AUTOSAR XML (schema 4-2-1)
standard types defined: boolean, float32, uint8, boolean_CompuMethod, boolean_DataConstr, float32_DataConstr, uint8_DataConstr
package /ComponentTypes
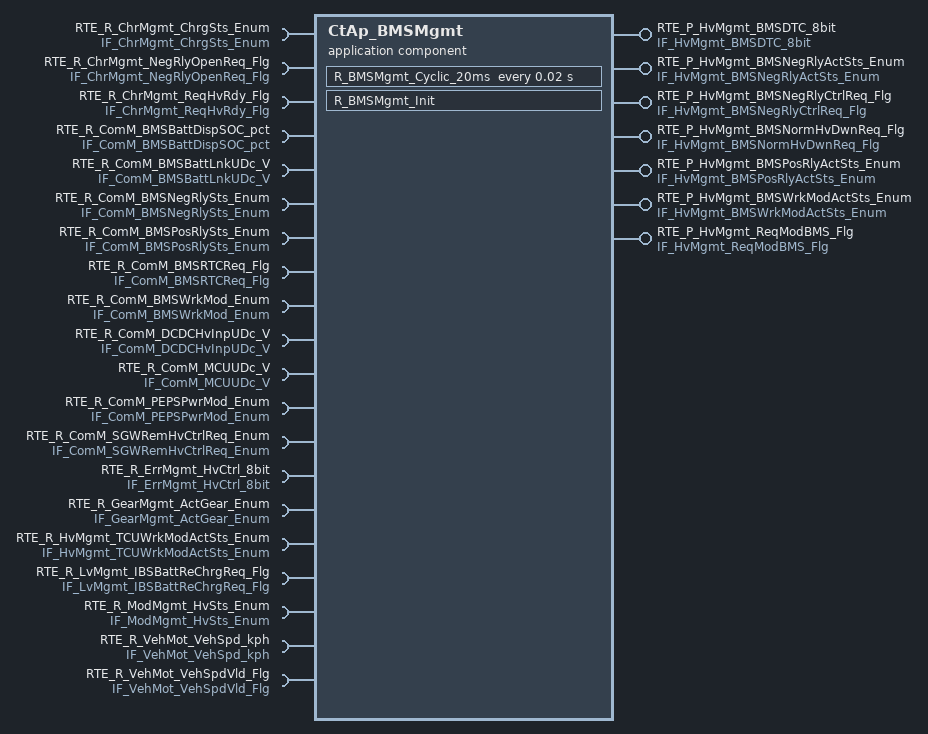
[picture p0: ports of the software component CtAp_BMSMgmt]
  application sw component type CtAp_BMSMgmt
    7 x provide port:
      RTE_P_HvMgmt_BMSDTC_8bit: nonqueued-sender-com-spec{data-element=tec_HvMgmt_BMSDTC_8bit, init-value=0}, provided-interface=IF_HvMgmt_BMSDTC_8bit
      RTE_P_HvMgmt_BMSNegRlyActSts_Enum: nonqueued-sender-com-spec{data-element=tec_HvMgmt_BMSNegRlyActSts_Enum, init-value=0}, provided-interface=IF_HvMgmt_BMSNegRlyActSts_Enum
      RTE_P_HvMgmt_BMSNegRlyCtrlReq_Flg: nonqueued-sender-com-spec{data-element=tec_HvMgmt_BMSNegRlyCtrlReq_Flg, init-value=0}, provided-interface=IF_HvMgmt_BMSNegRlyCtrlReq_Flg
      RTE_P_HvMgmt_BMSNormHvDwnReq_Flg: nonqueued-sender-com-spec{data-element=tec_HvMgmt_BMSNormHvDwnReq_Flg, init-value=0}, provided-interface=IF_HvMgmt_BMSNormHvDwnReq_Flg
      RTE_P_HvMgmt_BMSPosRlyActSts_Enum: nonqueued-sender-com-spec{data-element=tec_HvMgmt_BMSPosRlyActSts_Enum, init-value=0}, provided-interface=IF_HvMgmt_BMSPosRlyActSts_Enum
      RTE_P_HvMgmt_BMSWrkModActSts_Enum: nonqueued-sender-com-spec{data-element=tec_HvMgmt_BMSWrkModActSts_Enum, init-value=0}, provided-interface=IF_HvMgmt_BMSWrkModActSts_Enum
      RTE_P_HvMgmt_ReqModBMS_Flg: nonqueued-sender-com-spec{data-element=tec_HvMgmt_ReqModBMS_Flg, init-value=0}, provided-interface=IF_HvMgmt_ReqModBMS_Flg
    20 x require port:
      RTE_R_ChrMgmt_ChrgSts_Enum: nonqueued-receiver-com-spec{data-element=tec_ChrMgmt_ChrgSts_Enum, filter=data-filter-type=ALWAYS, init-value=0}, required-interface=IF_ChrMgmt_ChrgSts_Enum
      RTE_R_ChrMgmt_NegRlyOpenReq_Flg: nonqueued-receiver-com-spec{data-element=tec_ChrMgmt_NegRlyOpenReq_Flg, filter=data-filter-type=ALWAYS, init-value=0}, required-interface=IF_ChrMgmt_NegRlyOpenReq_Flg
      RTE_R_ChrMgmt_ReqHvRdy_Flg: nonqueued-receiver-com-spec{data-element=tec_ChrMgmt_ReqHvRdy_Flg, filter=data-filter-type=ALWAYS, init-value=0}, required-interface=IF_ChrMgmt_ReqHvRdy_Flg
      RTE_R_ComM_BMSBattDispSOC_pct: nonqueued-receiver-com-spec{data-element=tec_ComM_BMSBattDispSOC_pct, filter=data-filter-type=ALWAYS, init-value=0}, required-interface=IF_ComM_BMSBattDispSOC_pct
      RTE_R_ComM_BMSBattLnkUDc_V: nonqueued-receiver-com-spec{data-element=tec_ComM_BMSBattLnkUDc_V, filter=data-filter-type=ALWAYS, init-value=0}, required-interface=IF_ComM_BMSBattLnkUDc_V
      RTE_R_ComM_BMSNegRlySts_Enum: nonqueued-receiver-com-spec{data-element=tec_ComM_BMSNegRlySts_Enum, filter=data-filter-type=ALWAYS, init-value=0}, required-interface=IF_ComM_BMSNegRlySts_Enum
      RTE_R_ComM_BMSPosRlySts_Enum: nonqueued-receiver-com-spec{data-element=tec_ComM_BMSPosRlySts_Enum, filter=data-filter-type=ALWAYS, init-value=0}, required-interface=IF_ComM_BMSPosRlySts_Enum
      RTE_R_ComM_BMSRTCReq_Flg: nonqueued-receiver-com-spec{data-element=tec_ComM_BMSRTCReq_Flg, filter=data-filter-type=ALWAYS, init-value=0}, required-interface=IF_ComM_BMSRTCReq_Flg
      RTE_R_ComM_BMSWrkMod_Enum: nonqueued-receiver-com-spec{data-element=tec_ComM_BMSWrkMod_Enum, filter=data-filter-type=ALWAYS, init-value=0}, required-interface=IF_ComM_BMSWrkMod_Enum
      RTE_R_ComM_DCDCHvInpUDc_V: nonqueued-receiver-com-spec{data-element=tec_ComM_DCDCHvInpUDc_V, filter=data-filter-type=ALWAYS, init-value=0}, required-interface=IF_ComM_DCDCHvInpUDc_V
      RTE_R_ComM_MCUUDc_V: nonqueued-receiver-com-spec{data-element=tec_ComM_MCUUDc_V, filter=data-filter-type=ALWAYS, init-value=0}, required-interface=IF_ComM_MCUUDc_V
      RTE_R_ComM_PEPSPwrMod_Enum: nonqueued-receiver-com-spec{data-element=tec_ComM_PEPSPwrMod_Enum, filter=data-filter-type=ALWAYS, init-value=0}, required-interface=IF_ComM_PEPSPwrMod_Enum
      RTE_R_ComM_SGWRemHvCtrlReq_Enum: nonqueued-receiver-com-spec{data-element=tec_ComM_SGWRemHvCtrlReq_Enum, filter=data-filter-type=ALWAYS, init-value=0}, required-interface=IF_ComM_SGWRemHvCtrlReq_Enum
      RTE_R_ErrMgmt_HvCtrl_8bit: nonqueued-receiver-com-spec{data-element=tec_ErrMgmt_HvCtrl_8bit, filter=data-filter-type=ALWAYS, init-value=0}, required-interface=IF_ErrMgmt_HvCtrl_8bit
      RTE_R_GearMgmt_ActGear_Enum: nonqueued-receiver-com-spec{data-element=tec_GearMgmt_ActGear_Enum, filter=data-filter-type=ALWAYS, init-value=0}, required-interface=IF_GearMgmt_ActGear_Enum
      RTE_R_HvMgmt_TCUWrkModActSts_Enum: nonqueued-receiver-com-spec{data-element=tec_HvMgmt_TCUWrkModActSts_Enum, filter=data-filter-type=ALWAYS, init-value=0}, required-interface=IF_HvMgmt_TCUWrkModActSts_Enum
      RTE_R_LvMgmt_IBSBattReChrgReq_Flg: nonqueued-receiver-com-spec{data-element=tec_LvMgmt_IBSBattReChrgReq_Flg, filter=data-filter-type=ALWAYS, init-value=0}, required-interface=IF_LvMgmt_IBSBattReChrgReq_Flg
      RTE_R_ModMgmt_HvSts_Enum: nonqueued-receiver-com-spec{data-element=tec_ModMgmt_HvSts_Enum, filter=data-filter-type=ALWAYS, init-value=0}, required-interface=IF_ModMgmt_HvSts_Enum
      RTE_R_VehMot_VehSpd_kph: nonqueued-receiver-com-spec{data-element=tec_VehMot_VehSpd_kph, filter=data-filter-type=ALWAYS, init-value=0}, required-interface=IF_VehMot_VehSpd_kph
      RTE_R_VehMot_VehSpdVld_Flg: nonqueued-receiver-com-spec{data-element=tec_VehMot_VehSpdVld_Flg, filter=data-filter-type=ALWAYS, init-value=0}, required-interface=IF_VehMot_VehSpdVld_Flg
    behavior CtAp_BMSMgmt_InternalBehavior
      timing event TMT_R_BMSMgmt_Cyclic_20ms: start-on-event=R_BMSMgmt_Cyclic_20ms, period=0.02
      init event CtAp_BMSMgmt_InitEvent: start-on-event=R_BMSMgmt_Init
      runnable R_BMSMgmt_Cyclic_20ms
        data-receive-point-by-arguments:
          20 x access:
            REC_RTE_R_ChrMgmt_ChrgSts_Enum_tec_ChrMgmt_ChrgSts_Enum: accessed-variable=RTE_R_ChrMgmt_ChrgSts_Enum.tec_ChrMgmt_ChrgSts_Enum
            REC_RTE_R_ChrMgmt_NegRlyOpenReq_Flg_tec_ChrMgmt_NegRlyOpenReq_Flg: accessed-variable=RTE_R_ChrMgmt_NegRlyOpenReq_Flg.tec_ChrMgmt_NegRlyOpenReq_Flg
            REC_RTE_R_ChrMgmt_ReqHvRdy_Flg_tec_ChrMgmt_ReqHvRdy_Flg: accessed-variable=RTE_R_ChrMgmt_ReqHvRdy_Flg.tec_ChrMgmt_ReqHvRdy_Flg
            REC_RTE_R_ComM_BMSBattDispSOC_pct_tec_ComM_BMSBattDispSOC_pct: accessed-variable=RTE_R_ComM_BMSBattDispSOC_pct.tec_ComM_BMSBattDispSOC_pct
            REC_RTE_R_ComM_BMSBattLnkUDc_V_tec_ComM_BMSBattLnkUDc_V: accessed-variable=RTE_R_ComM_BMSBattLnkUDc_V.tec_ComM_BMSBattLnkUDc_V
            REC_RTE_R_ComM_BMSNegRlySts_Enum_tec_ComM_BMSNegRlySts_Enum: accessed-variable=RTE_R_ComM_BMSNegRlySts_Enum.tec_ComM_BMSNegRlySts_Enum
            REC_RTE_R_ComM_BMSPosRlySts_Enum_tec_ComM_BMSPosRlySts_Enum: accessed-variable=RTE_R_ComM_BMSPosRlySts_Enum.tec_ComM_BMSPosRlySts_Enum
            REC_RTE_R_ComM_BMSRTCReq_Flg_tec_ComM_BMSRTCReq_Flg: accessed-variable=RTE_R_ComM_BMSRTCReq_Flg.tec_ComM_BMSRTCReq_Flg
            REC_RTE_R_ComM_BMSWrkMod_Enum_tec_ComM_BMSWrkMod_Enum: accessed-variable=RTE_R_ComM_BMSWrkMod_Enum.tec_ComM_BMSWrkMod_Enum
            REC_RTE_R_ComM_DCDCHvInpUDc_V_tec_ComM_DCDCHvInpUDc_V: accessed-variable=RTE_R_ComM_DCDCHvInpUDc_V.tec_ComM_DCDCHvInpUDc_V
            REC_RTE_R_ComM_MCUUDc_V_tec_ComM_MCUUDc_V: accessed-variable=RTE_R_ComM_MCUUDc_V.tec_ComM_MCUUDc_V
            REC_RTE_R_ComM_PEPSPwrMod_Enum_tec_ComM_PEPSPwrMod_Enum: accessed-variable=RTE_R_ComM_PEPSPwrMod_Enum.tec_ComM_PEPSPwrMod_Enum
            REC_RTE_R_ComM_SGWRemHvCtrlReq_Enum_tec_ComM_SGWRemHvCtrlReq_Enum: accessed-variable=RTE_R_ComM_SGWRemHvCtrlReq_Enum.tec_ComM_SGWRemHvCtrlReq_Enum
            REC_RTE_R_ErrMgmt_HvCtrl_8bit_tec_ErrMgmt_HvCtrl_8bit: accessed-variable=RTE_R_ErrMgmt_HvCtrl_8bit.tec_ErrMgmt_HvCtrl_8bit
            REC_RTE_R_GearMgmt_ActGear_Enum_tec_GearMgmt_ActGear_Enum: accessed-variable=RTE_R_GearMgmt_ActGear_Enum.tec_GearMgmt_ActGear_Enum
            REC_RTE_R_HvMgmt_TCUWrkModActSts_Enum_tec_HvMgmt_TCUWrkModActSts_Enum: accessed-variable=RTE_R_HvMgmt_TCUWrkModActSts_Enum.tec_HvMgmt_TCUWrkModActSts_Enum
            REC_RTE_R_LvMgmt_IBSBattReChrgReq_Flg_tec_LvMgmt_IBSBattReChrgReq_Flg: accessed-variable=RTE_R_LvMgmt_IBSBattReChrgReq_Flg.tec_LvMgmt_IBSBattReChrgReq_Flg
            REC_RTE_R_ModMgmt_HvSts_Enum_tec_ModMgmt_HvSts_Enum: accessed-variable=RTE_R_ModMgmt_HvSts_Enum.tec_ModMgmt_HvSts_Enum
            REC_RTE_R_VehMot_VehSpd_kph_tec_VehMot_VehSpd_kph: accessed-variable=RTE_R_VehMot_VehSpd_kph.tec_VehMot_VehSpd_kph
            REC_RTE_R_VehMot_VehSpdVld_Flg_tec_VehMot_VehSpdVld_Flg: accessed-variable=RTE_R_VehMot_VehSpdVld_Flg.tec_VehMot_VehSpdVld_Flg
        data-send-points:
          7 x access:
            SEND_RTE_P_HvMgmt_BMSDTC_8bit_tec_HvMgmt_BMSDTC_8bit: accessed-variable=RTE_P_HvMgmt_BMSDTC_8bit.tec_HvMgmt_BMSDTC_8bit
            SEND_RTE_P_HvMgmt_BMSNegRlyActSts_Enum_tec_HvMgmt_BMSNegRlyActSts_Enum: accessed-variable=RTE_P_HvMgmt_BMSNegRlyActSts_Enum.tec_HvMgmt_BMSNegRlyActSts_Enum
            SEND_RTE_P_HvMgmt_BMSNegRlyCtrlReq_Flg_tec_HvMgmt_BMSNegRlyCtrlReq_Flg: accessed-variable=RTE_P_HvMgmt_BMSNegRlyCtrlReq_Flg.tec_HvMgmt_BMSNegRlyCtrlReq_Flg
            SEND_RTE_P_HvMgmt_BMSNormHvDwnReq_Flg_tec_HvMgmt_BMSNormHvDwnReq_Flg: accessed-variable=RTE_P_HvMgmt_BMSNormHvDwnReq_Flg.tec_HvMgmt_BMSNormHvDwnReq_Flg
            SEND_RTE_P_HvMgmt_BMSPosRlyActSts_Enum_tec_HvMgmt_BMSPosRlyActSts_Enum: accessed-variable=RTE_P_HvMgmt_BMSPosRlyActSts_Enum.tec_HvMgmt_BMSPosRlyActSts_Enum
            SEND_RTE_P_HvMgmt_BMSWrkModActSts_Enum_tec_HvMgmt_BMSWrkModActSts_Enum: accessed-variable=RTE_P_HvMgmt_BMSWrkModActSts_Enum.tec_HvMgmt_BMSWrkModActSts_Enum
            SEND_RTE_P_HvMgmt_ReqModBMS_Flg_tec_HvMgmt_ReqModBMS_Flg: accessed-variable=RTE_P_HvMgmt_ReqModBMS_Flg.tec_HvMgmt_ReqModBMS_Flg
      runnable R_BMSMgmt_Init
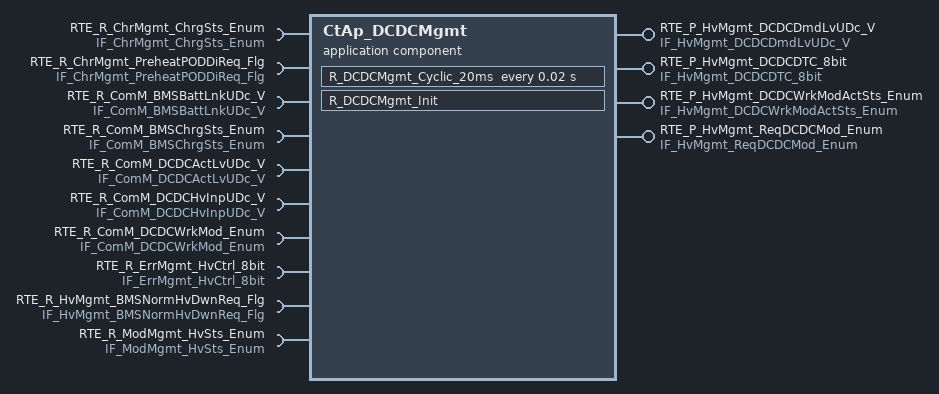
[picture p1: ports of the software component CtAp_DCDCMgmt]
  application sw component type CtAp_DCDCMgmt
    4 x provide port:
      RTE_P_HvMgmt_DCDCDmdLvUDc_V: nonqueued-sender-com-spec{data-element=tec_HvMgmt_DCDCDmdLvUDc_V, init-value=0}, provided-interface=IF_HvMgmt_DCDCDmdLvUDc_V
      RTE_P_HvMgmt_DCDCDTC_8bit: nonqueued-sender-com-spec{data-element=tec_HvMgmt_DCDCDTC_8bit, init-value=0}, provided-interface=IF_HvMgmt_DCDCDTC_8bit
      RTE_P_HvMgmt_DCDCWrkModActSts_Enum: nonqueued-sender-com-spec{data-element=tec_HvMgmt_DCDCWrkModActSts_Enum, init-value=0}, provided-interface=IF_HvMgmt_DCDCWrkModActSts_Enum
      RTE_P_HvMgmt_ReqDCDCMod_Enum: nonqueued-sender-com-spec{data-element=tec_HvMgmt_ReqDCDCMod_Enum, init-value=0}, provided-interface=IF_HvMgmt_ReqDCDCMod_Enum
    10 x require port:
      RTE_R_ChrMgmt_ChrgSts_Enum: nonqueued-receiver-com-spec{data-element=tec_ChrMgmt_ChrgSts_Enum, filter=data-filter-type=ALWAYS, init-value=0}, required-interface=IF_ChrMgmt_ChrgSts_Enum
      RTE_R_ChrMgmt_PreheatPODDiReq_Flg: nonqueued-receiver-com-spec{data-element=tec_ChrMgmt_PreheatPODDiReq_Flg, filter=data-filter-type=ALWAYS, init-value=0}, required-interface=IF_ChrMgmt_PreheatPODDiReq_Flg
      RTE_R_ComM_BMSBattLnkUDc_V: nonqueued-receiver-com-spec{data-element=tec_ComM_BMSBattLnkUDc_V, filter=data-filter-type=ALWAYS, init-value=0}, required-interface=IF_ComM_BMSBattLnkUDc_V
      RTE_R_ComM_BMSChrgSts_Enum: nonqueued-receiver-com-spec{data-element=tec_ComM_BMSChrgSts_Enum, filter=data-filter-type=ALWAYS, init-value=0}, required-interface=IF_ComM_BMSChrgSts_Enum
      RTE_R_ComM_DCDCActLvUDc_V: nonqueued-receiver-com-spec{data-element=tec_ComM_DCDCActLvUDc_V, filter=data-filter-type=ALWAYS, init-value=0}, required-interface=IF_ComM_DCDCActLvUDc_V
      RTE_R_ComM_DCDCHvInpUDc_V: nonqueued-receiver-com-spec{data-element=tec_ComM_DCDCHvInpUDc_V, filter=data-filter-type=ALWAYS, init-value=0}, required-interface=IF_ComM_DCDCHvInpUDc_V
      RTE_R_ComM_DCDCWrkMod_Enum: nonqueued-receiver-com-spec{data-element=tec_ComM_DCDCWrkMod_Enum, filter=data-filter-type=ALWAYS, init-value=0}, required-interface=IF_ComM_DCDCWrkMod_Enum
      RTE_R_ErrMgmt_HvCtrl_8bit: nonqueued-receiver-com-spec{data-element=tec_ErrMgmt_HvCtrl_8bit, filter=data-filter-type=ALWAYS, init-value=0}, required-interface=IF_ErrMgmt_HvCtrl_8bit
      RTE_R_HvMgmt_BMSNormHvDwnReq_Flg: nonqueued-receiver-com-spec{data-element=tec_HvMgmt_BMSNormHvDwnReq_Flg, filter=data-filter-type=ALWAYS, init-value=0}, required-interface=IF_HvMgmt_BMSNormHvDwnReq_Flg
      RTE_R_ModMgmt_HvSts_Enum: nonqueued-receiver-com-spec{data-element=tec_ModMgmt_HvSts_Enum, filter=data-filter-type=ALWAYS, init-value=0}, required-interface=IF_ModMgmt_HvSts_Enum
    behavior CtAp_DCDCMgmt_InternalBehavior
      timing event TMT_R_DCDCMgmt_Cyclic_20ms: start-on-event=R_DCDCMgmt_Cyclic_20ms, period=0.02
      init event CtAp_DCDCMgmt_InitEvent: start-on-event=R_DCDCMgmt_Init
      runnable R_DCDCMgmt_Cyclic_20ms
        data-receive-point-by-arguments:
          10 x access:
            REC_RTE_R_ChrMgmt_ChrgSts_Enum_tec_ChrMgmt_ChrgSts_Enum: accessed-variable=RTE_R_ChrMgmt_ChrgSts_Enum.tec_ChrMgmt_ChrgSts_Enum
            REC_RTE_R_ChrMgmt_PreheatPODDiReq_Flg_tec_ChrMgmt_PreheatPODDiReq_Flg: accessed-variable=RTE_R_ChrMgmt_PreheatPODDiReq_Flg.tec_ChrMgmt_PreheatPODDiReq_Flg
            REC_RTE_R_ComM_BMSBattLnkUDc_V_tec_ComM_BMSBattLnkUDc_V: accessed-variable=RTE_R_ComM_BMSBattLnkUDc_V.tec_ComM_BMSBattLnkUDc_V
            REC_RTE_R_ComM_BMSChrgSts_Enum_tec_ComM_BMSChrgSts_Enum: accessed-variable=RTE_R_ComM_BMSChrgSts_Enum.tec_ComM_BMSChrgSts_Enum
            REC_RTE_R_ComM_DCDCActLvUDc_V_tec_ComM_DCDCActLvUDc_V: accessed-variable=RTE_R_ComM_DCDCActLvUDc_V.tec_ComM_DCDCActLvUDc_V
            REC_RTE_R_ComM_DCDCHvInpUDc_V_tec_ComM_DCDCHvInpUDc_V: accessed-variable=RTE_R_ComM_DCDCHvInpUDc_V.tec_ComM_DCDCHvInpUDc_V
            REC_RTE_R_ComM_DCDCWrkMod_Enum_tec_ComM_DCDCWrkMod_Enum: accessed-variable=RTE_R_ComM_DCDCWrkMod_Enum.tec_ComM_DCDCWrkMod_Enum
            REC_RTE_R_ErrMgmt_HvCtrl_8bit_tec_ErrMgmt_HvCtrl_8bit: accessed-variable=RTE_R_ErrMgmt_HvCtrl_8bit.tec_ErrMgmt_HvCtrl_8bit
            REC_RTE_R_HvMgmt_BMSNormHvDwnReq_Flg_tec_HvMgmt_BMSNormHvDwnReq_Flg: accessed-variable=RTE_R_HvMgmt_BMSNormHvDwnReq_Flg.tec_HvMgmt_BMSNormHvDwnReq_Flg
            REC_RTE_R_ModMgmt_HvSts_Enum_tec_ModMgmt_HvSts_Enum: accessed-variable=RTE_R_ModMgmt_HvSts_Enum.tec_ModMgmt_HvSts_Enum
        data-send-points:
          4 x access:
            SEND_RTE_P_HvMgmt_DCDCDmdLvUDc_V_tec_HvMgmt_DCDCDmdLvUDc_V: accessed-variable=RTE_P_HvMgmt_DCDCDmdLvUDc_V.tec_HvMgmt_DCDCDmdLvUDc_V
            SEND_RTE_P_HvMgmt_DCDCDTC_8bit_tec_HvMgmt_DCDCDTC_8bit: accessed-variable=RTE_P_HvMgmt_DCDCDTC_8bit.tec_HvMgmt_DCDCDTC_8bit
            SEND_RTE_P_HvMgmt_DCDCWrkModActSts_Enum_tec_HvMgmt_DCDCWrkModActSts_Enum: accessed-variable=RTE_P_HvMgmt_DCDCWrkModActSts_Enum.tec_HvMgmt_DCDCWrkModActSts_Enum
            SEND_RTE_P_HvMgmt_ReqDCDCMod_Enum_tec_HvMgmt_ReqDCDCMod_Enum: accessed-variable=RTE_P_HvMgmt_ReqDCDCMod_Enum.tec_HvMgmt_ReqDCDCMod_Enum
      runnable R_DCDCMgmt_Init
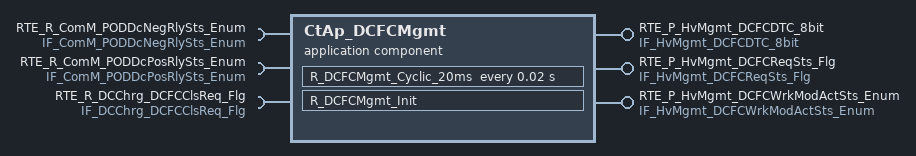
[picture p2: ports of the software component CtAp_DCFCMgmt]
  application sw component type CtAp_DCFCMgmt
    provide port RTE_P_HvMgmt_DCFCDTC_8bit: nonqueued-sender-com-spec{data-element=tec_HvMgmt_DCFCDTC_8bit, init-value=0}, provided-interface=IF_HvMgmt_DCFCDTC_8bit
    provide port RTE_P_HvMgmt_DCFCReqSts_Flg: nonqueued-sender-com-spec{data-element=tec_HvMgmt_DCFCReqSts_Flg, init-value=0}, provided-interface=IF_HvMgmt_DCFCReqSts_Flg
    provide port RTE_P_HvMgmt_DCFCWrkModActSts_Enum: nonqueued-sender-com-spec{data-element=tec_HvMgmt_DCFCWrkModActSts_Enum, init-value=0}, provided-interface=IF_HvMgmt_DCFCWrkModActSts_Enum
    require port RTE_R_ComM_PODDcNegRlySts_Enum: nonqueued-receiver-com-spec{data-element=tec_ComM_PODDcNegRlySts_Enum, filter=data-filter-type=ALWAYS, init-value=0}, required-interface=IF_ComM_PODDcNegRlySts_Enum
    require port RTE_R_ComM_PODDcPosRlySts_Enum: nonqueued-receiver-com-spec{data-element=tec_ComM_PODDcPosRlySts_Enum, filter=data-filter-type=ALWAYS, init-value=0}, required-interface=IF_ComM_PODDcPosRlySts_Enum
    require port RTE_R_DCChrg_DCFCClsReq_Flg: nonqueued-receiver-com-spec{data-element=tec_DCChrg_DCFCClsReq_Flg, filter=data-filter-type=ALWAYS, init-value=0}, required-interface=IF_DCChrg_DCFCClsReq_Flg
    behavior CtAp_DCFCMgmt_InternalBehavior
      timing event TMT_R_DCFCMgmt_Cyclic_20ms: start-on-event=R_DCFCMgmt_Cyclic_20ms, period=0.02
      init event CtAp_DCFCMgmt_InitEvent: start-on-event=R_DCFCMgmt_Init
      runnable R_DCFCMgmt_Cyclic_20ms
        data-receive-point-by-arguments:
          access REC_RTE_R_ComM_PODDcNegRlySts_Enum_tec_ComM_PODDcNegRlySts_Enum: accessed-variable=RTE_R_ComM_PODDcNegRlySts_Enum.tec_ComM_PODDcNegRlySts_Enum
          access REC_RTE_R_ComM_PODDcPosRlySts_Enum_tec_ComM_PODDcPosRlySts_Enum: accessed-variable=RTE_R_ComM_PODDcPosRlySts_Enum.tec_ComM_PODDcPosRlySts_Enum
          access REC_RTE_R_DCChrg_DCFCClsReq_Flg_tec_DCChrg_DCFCClsReq_Flg: accessed-variable=RTE_R_DCChrg_DCFCClsReq_Flg.tec_DCChrg_DCFCClsReq_Flg
        data-send-points:
          access SEND_RTE_P_HvMgmt_DCFCDTC_8bit_tec_HvMgmt_DCFCDTC_8bit: accessed-variable=RTE_P_HvMgmt_DCFCDTC_8bit.tec_HvMgmt_DCFCDTC_8bit
          access SEND_RTE_P_HvMgmt_DCFCReqSts_Flg_tec_HvMgmt_DCFCReqSts_Flg: accessed-variable=RTE_P_HvMgmt_DCFCReqSts_Flg.tec_HvMgmt_DCFCReqSts_Flg
          access SEND_RTE_P_HvMgmt_DCFCWrkModActSts_Enum_tec_HvMgmt_DCFCWrkModActSts_Enum: accessed-variable=RTE_P_HvMgmt_DCFCWrkModActSts_Enum.tec_HvMgmt_DCFCWrkModActSts_Enum
      runnable R_DCFCMgmt_Init
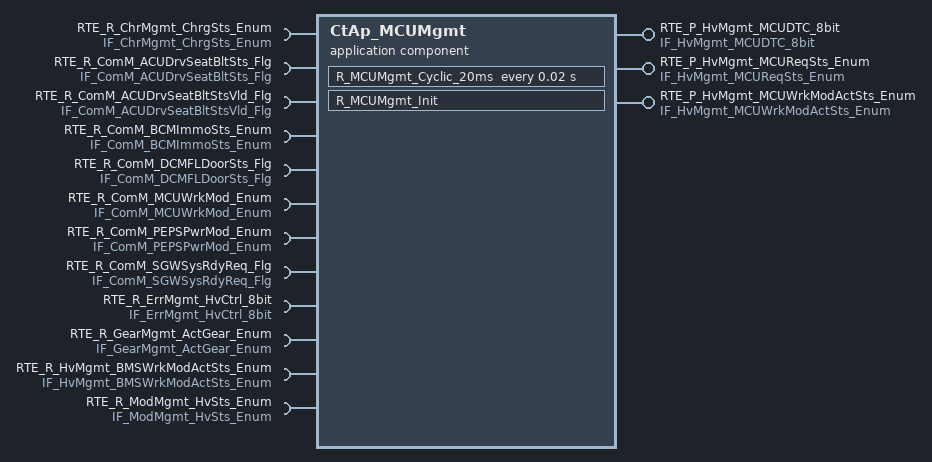
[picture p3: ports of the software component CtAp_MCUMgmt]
  application sw component type CtAp_MCUMgmt
    provide port RTE_P_HvMgmt_MCUDTC_8bit: nonqueued-sender-com-spec{data-element=tec_HvMgmt_MCUDTC_8bit, init-value=0}, provided-interface=IF_HvMgmt_MCUDTC_8bit
    provide port RTE_P_HvMgmt_MCUReqSts_Enum: nonqueued-sender-com-spec{data-element=tec_HvMgmt_MCUReqSts_Enum, init-value=0}, provided-interface=IF_HvMgmt_MCUReqSts_Enum
    provide port RTE_P_HvMgmt_MCUWrkModActSts_Enum: nonqueued-sender-com-spec{data-element=tec_HvMgmt_MCUWrkModActSts_Enum, init-value=0}, provided-interface=IF_HvMgmt_MCUWrkModActSts_Enum
    12 x require port:
      RTE_R_ChrMgmt_ChrgSts_Enum: nonqueued-receiver-com-spec{data-element=tec_ChrMgmt_ChrgSts_Enum, filter=data-filter-type=ALWAYS, init-value=0}, required-interface=IF_ChrMgmt_ChrgSts_Enum
      RTE_R_ComM_ACUDrvSeatBltSts_Flg: nonqueued-receiver-com-spec{data-element=tec_ComM_ACUDrvSeatBltSts_Flg, filter=data-filter-type=ALWAYS, init-value=0}, required-interface=IF_ComM_ACUDrvSeatBltSts_Flg
      RTE_R_ComM_ACUDrvSeatBltStsVld_Flg: nonqueued-receiver-com-spec{data-element=tec_ComM_ACUDrvSeatBltStsVld_Flg, filter=data-filter-type=ALWAYS, init-value=0}, required-interface=IF_ComM_ACUDrvSeatBltStsVld_Flg
      RTE_R_ComM_BCMImmoSts_Enum: nonqueued-receiver-com-spec{data-element=tec_ComM_BCMImmoSts_Enum, filter=data-filter-type=ALWAYS, init-value=0}, required-interface=IF_ComM_BCMImmoSts_Enum
      RTE_R_ComM_DCMFLDoorSts_Flg: nonqueued-receiver-com-spec{data-element=tec_ComM_DCMFLDoorSts_Flg, filter=data-filter-type=ALWAYS, init-value=0}, required-interface=IF_ComM_DCMFLDoorSts_Flg
      RTE_R_ComM_MCUWrkMod_Enum: nonqueued-receiver-com-spec{data-element=tec_ComM_MCUWrkMod_Enum, filter=data-filter-type=ALWAYS, init-value=0}, required-interface=IF_ComM_MCUWrkMod_Enum
      RTE_R_ComM_PEPSPwrMod_Enum: nonqueued-receiver-com-spec{data-element=tec_ComM_PEPSPwrMod_Enum, filter=data-filter-type=ALWAYS, init-value=0}, required-interface=IF_ComM_PEPSPwrMod_Enum
      RTE_R_ComM_SGWSysRdyReq_Flg: nonqueued-receiver-com-spec{data-element=tec_ComM_SGWSysRdyReq_Flg, filter=data-filter-type=ALWAYS, init-value=0}, required-interface=IF_ComM_SGWSysRdyReq_Flg
      RTE_R_ErrMgmt_HvCtrl_8bit: nonqueued-receiver-com-spec{data-element=tec_ErrMgmt_HvCtrl_8bit, filter=data-filter-type=ALWAYS, init-value=0}, required-interface=IF_ErrMgmt_HvCtrl_8bit
      RTE_R_GearMgmt_ActGear_Enum: nonqueued-receiver-com-spec{data-element=tec_GearMgmt_ActGear_Enum, filter=data-filter-type=ALWAYS, init-value=0}, required-interface=IF_GearMgmt_ActGear_Enum
      RTE_R_HvMgmt_BMSWrkModActSts_Enum: nonqueued-receiver-com-spec{data-element=tec_HvMgmt_BMSWrkModActSts_Enum, filter=data-filter-type=ALWAYS, init-value=0}, required-interface=IF_HvMgmt_BMSWrkModActSts_Enum
      RTE_R_ModMgmt_HvSts_Enum: nonqueued-receiver-com-spec{data-element=tec_ModMgmt_HvSts_Enum, filter=data-filter-type=ALWAYS, init-value=0}, required-interface=IF_ModMgmt_HvSts_Enum
    behavior CtAp_MCUMgmt_InternalBehavior
      timing event TMT_R_MCUMgmt_Cyclic_20ms: start-on-event=R_MCUMgmt_Cyclic_20ms, period=0.02
      init event CtAp_MCUMgmt_InitEvent: start-on-event=R_MCUMgmt_Init
      runnable R_MCUMgmt_Cyclic_20ms
        data-receive-point-by-arguments:
          12 x access:
            REC_RTE_R_ChrMgmt_ChrgSts_Enum_tec_ChrMgmt_ChrgSts_Enum: accessed-variable=RTE_R_ChrMgmt_ChrgSts_Enum.tec_ChrMgmt_ChrgSts_Enum
            REC_RTE_R_ComM_ACUDrvSeatBltSts_Flg_tec_ComM_ACUDrvSeatBltSts_Flg: accessed-variable=RTE_R_ComM_ACUDrvSeatBltSts_Flg.tec_ComM_ACUDrvSeatBltSts_Flg
            REC_RTE_R_ComM_ACUDrvSeatBltStsVld_Flg_tec_ComM_ACUDrvSeatBltStsVld_Flg: accessed-variable=RTE_R_ComM_ACUDrvSeatBltStsVld_Flg.tec_ComM_ACUDrvSeatBltStsVld_Flg
            REC_RTE_R_ComM_BCMImmoSts_Enum_tec_ComM_BCMImmoSts_Enum: accessed-variable=RTE_R_ComM_BCMImmoSts_Enum.tec_ComM_BCMImmoSts_Enum
            REC_RTE_R_ComM_DCMFLDoorSts_Flg_tec_ComM_DCMFLDoorSts_Flg: accessed-variable=RTE_R_ComM_DCMFLDoorSts_Flg.tec_ComM_DCMFLDoorSts_Flg
            REC_RTE_R_ComM_MCUWrkMod_Enum_tec_ComM_MCUWrkMod_Enum: accessed-variable=RTE_R_ComM_MCUWrkMod_Enum.tec_ComM_MCUWrkMod_Enum
            REC_RTE_R_ComM_PEPSPwrMod_Enum_tec_ComM_PEPSPwrMod_Enum: accessed-variable=RTE_R_ComM_PEPSPwrMod_Enum.tec_ComM_PEPSPwrMod_Enum
            REC_RTE_R_ComM_SGWSysRdyReq_Flg_tec_ComM_SGWSysRdyReq_Flg: accessed-variable=RTE_R_ComM_SGWSysRdyReq_Flg.tec_ComM_SGWSysRdyReq_Flg
            REC_RTE_R_ErrMgmt_HvCtrl_8bit_tec_ErrMgmt_HvCtrl_8bit: accessed-variable=RTE_R_ErrMgmt_HvCtrl_8bit.tec_ErrMgmt_HvCtrl_8bit
            REC_RTE_R_GearMgmt_ActGear_Enum_tec_GearMgmt_ActGear_Enum: accessed-variable=RTE_R_GearMgmt_ActGear_Enum.tec_GearMgmt_ActGear_Enum
            REC_RTE_R_HvMgmt_BMSWrkModActSts_Enum_tec_HvMgmt_BMSWrkModActSts_Enum: accessed-variable=RTE_R_HvMgmt_BMSWrkModActSts_Enum.tec_HvMgmt_BMSWrkModActSts_Enum
            REC_RTE_R_ModMgmt_HvSts_Enum_tec_ModMgmt_HvSts_Enum: accessed-variable=RTE_R_ModMgmt_HvSts_Enum.tec_ModMgmt_HvSts_Enum
        data-send-points:
          access SEND_RTE_P_HvMgmt_MCUDTC_8bit_tec_HvMgmt_MCUDTC_8bit: accessed-variable=RTE_P_HvMgmt_MCUDTC_8bit.tec_HvMgmt_MCUDTC_8bit
          access SEND_RTE_P_HvMgmt_MCUReqSts_Enum_tec_HvMgmt_MCUReqSts_Enum: accessed-variable=RTE_P_HvMgmt_MCUReqSts_Enum.tec_HvMgmt_MCUReqSts_Enum
          access SEND_RTE_P_HvMgmt_MCUWrkModActSts_Enum_tec_HvMgmt_MCUWrkModActSts_Enum: accessed-variable=RTE_P_HvMgmt_MCUWrkModActSts_Enum.tec_HvMgmt_MCUWrkModActSts_Enum
      runnable R_MCUMgmt_Init
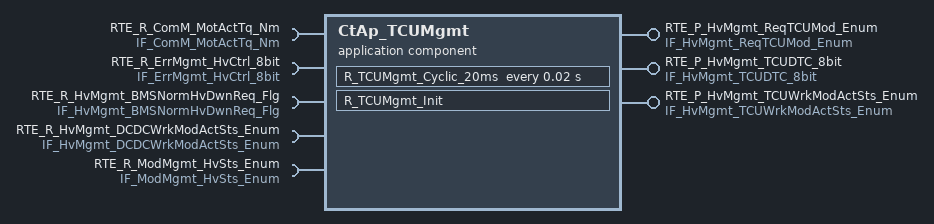
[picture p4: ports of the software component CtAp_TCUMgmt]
  application sw component type CtAp_TCUMgmt
    provide port RTE_P_HvMgmt_ReqTCUMod_Enum: nonqueued-sender-com-spec{data-element=tec_HvMgmt_ReqTCUMod_Enum, init-value=0}, provided-interface=IF_HvMgmt_ReqTCUMod_Enum
    provide port RTE_P_HvMgmt_TCUDTC_8bit: nonqueued-sender-com-spec{data-element=tec_HvMgmt_TCUDTC_8bit, init-value=0}, provided-interface=IF_HvMgmt_TCUDTC_8bit
    provide port RTE_P_HvMgmt_TCUWrkModActSts_Enum: nonqueued-sender-com-spec{data-element=tec_HvMgmt_TCUWrkModActSts_Enum, init-value=0}, provided-interface=IF_HvMgmt_TCUWrkModActSts_Enum
    5 x require port:
      RTE_R_ComM_MotActTq_Nm: nonqueued-receiver-com-spec{data-element=tec_ComM_MotActTq_Nm, filter=data-filter-type=ALWAYS, init-value=0}, required-interface=IF_ComM_MotActTq_Nm
      RTE_R_ErrMgmt_HvCtrl_8bit: nonqueued-receiver-com-spec{data-element=tec_ErrMgmt_HvCtrl_8bit, filter=data-filter-type=ALWAYS, init-value=0}, required-interface=IF_ErrMgmt_HvCtrl_8bit
      RTE_R_HvMgmt_BMSNormHvDwnReq_Flg: nonqueued-receiver-com-spec{data-element=tec_HvMgmt_BMSNormHvDwnReq_Flg, filter=data-filter-type=ALWAYS, init-value=0}, required-interface=IF_HvMgmt_BMSNormHvDwnReq_Flg
      RTE_R_HvMgmt_DCDCWrkModActSts_Enum: nonqueued-receiver-com-spec{data-element=tec_HvMgmt_DCDCWrkModActSts_Enum, filter=data-filter-type=ALWAYS, init-value=0}, required-interface=IF_HvMgmt_DCDCWrkModActSts_Enum
      RTE_R_ModMgmt_HvSts_Enum: nonqueued-receiver-com-spec{data-element=tec_ModMgmt_HvSts_Enum, filter=data-filter-type=ALWAYS, init-value=0}, required-interface=IF_ModMgmt_HvSts_Enum
    behavior CtAp_TCUMgmt_InternalBehavior
      timing event TMT_R_TCUMgmt_Cyclic_20ms: start-on-event=R_TCUMgmt_Cyclic_20ms, period=0.02
      init event CtAp_TCUMgmt_InitEvent: start-on-event=R_TCUMgmt_Init
      runnable R_TCUMgmt_Cyclic_20ms
        data-receive-point-by-arguments:
          5 x access:
            REC_RTE_R_ComM_MotActTq_Nm_tec_ComM_MotActTq_Nm: accessed-variable=RTE_R_ComM_MotActTq_Nm.tec_ComM_MotActTq_Nm
            REC_RTE_R_ErrMgmt_HvCtrl_8bit_tec_ErrMgmt_HvCtrl_8bit: accessed-variable=RTE_R_ErrMgmt_HvCtrl_8bit.tec_ErrMgmt_HvCtrl_8bit
            REC_RTE_R_HvMgmt_BMSNormHvDwnReq_Flg_tec_HvMgmt_BMSNormHvDwnReq_Flg: accessed-variable=RTE_R_HvMgmt_BMSNormHvDwnReq_Flg.tec_HvMgmt_BMSNormHvDwnReq_Flg
            REC_RTE_R_HvMgmt_DCDCWrkModActSts_Enum_tec_HvMgmt_DCDCWrkModActSts_Enum: accessed-variable=RTE_R_HvMgmt_DCDCWrkModActSts_Enum.tec_HvMgmt_DCDCWrkModActSts_Enum
            REC_RTE_R_ModMgmt_HvSts_Enum_tec_ModMgmt_HvSts_Enum: accessed-variable=RTE_R_ModMgmt_HvSts_Enum.tec_ModMgmt_HvSts_Enum
        data-send-points:
          access SEND_RTE_P_HvMgmt_ReqTCUMod_Enum_tec_HvMgmt_ReqTCUMod_Enum: accessed-variable=RTE_P_HvMgmt_ReqTCUMod_Enum.tec_HvMgmt_ReqTCUMod_Enum
          access SEND_RTE_P_HvMgmt_TCUDTC_8bit_tec_HvMgmt_TCUDTC_8bit: accessed-variable=RTE_P_HvMgmt_TCUDTC_8bit.tec_HvMgmt_TCUDTC_8bit
          access SEND_RTE_P_HvMgmt_TCUWrkModActSts_Enum_tec_HvMgmt_TCUWrkModActSts_Enum: accessed-variable=RTE_P_HvMgmt_TCUWrkModActSts_Enum.tec_HvMgmt_TCUWrkModActSts_Enum
      runnable R_TCUMgmt_Init
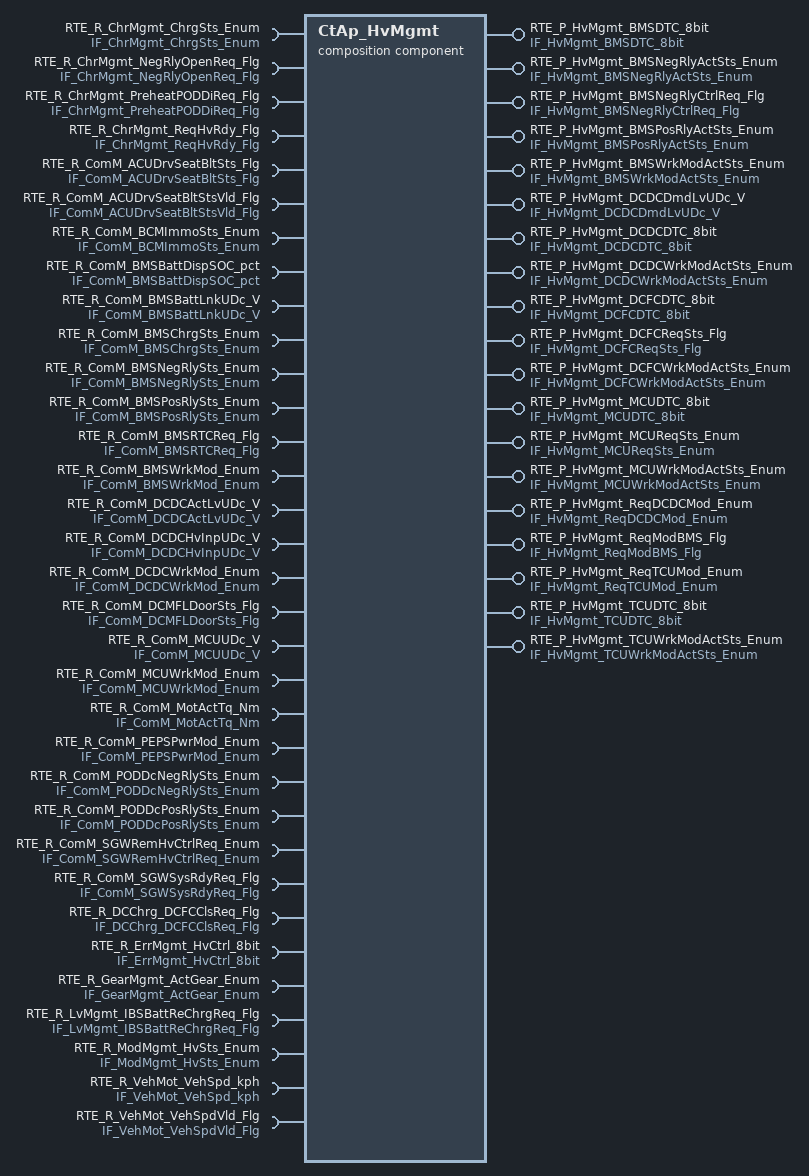
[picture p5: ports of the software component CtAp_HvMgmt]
  composition sw component type CtAp_HvMgmt
    19 x provide port:
      RTE_P_HvMgmt_BMSDTC_8bit: nonqueued-sender-com-spec=data-element=tec_HvMgmt_BMSDTC_8bit, provided-interface=IF_HvMgmt_BMSDTC_8bit
      RTE_P_HvMgmt_BMSNegRlyActSts_Enum: nonqueued-sender-com-spec=data-element=tec_HvMgmt_BMSNegRlyActSts_Enum, provided-interface=IF_HvMgmt_BMSNegRlyActSts_Enum
      RTE_P_HvMgmt_BMSNegRlyCtrlReq_Flg: nonqueued-sender-com-spec=data-element=tec_HvMgmt_BMSNegRlyCtrlReq_Flg, provided-interface=IF_HvMgmt_BMSNegRlyCtrlReq_Flg
      RTE_P_HvMgmt_BMSPosRlyActSts_Enum: nonqueued-sender-com-spec=data-element=tec_HvMgmt_BMSPosRlyActSts_Enum, provided-interface=IF_HvMgmt_BMSPosRlyActSts_Enum
      RTE_P_HvMgmt_BMSWrkModActSts_Enum: nonqueued-sender-com-spec=data-element=tec_HvMgmt_BMSWrkModActSts_Enum, provided-interface=IF_HvMgmt_BMSWrkModActSts_Enum
      RTE_P_HvMgmt_DCDCDmdLvUDc_V: nonqueued-sender-com-spec=data-element=tec_HvMgmt_DCDCDmdLvUDc_V, provided-interface=IF_HvMgmt_DCDCDmdLvUDc_V
      RTE_P_HvMgmt_DCDCDTC_8bit: nonqueued-sender-com-spec=data-element=tec_HvMgmt_DCDCDTC_8bit, provided-interface=IF_HvMgmt_DCDCDTC_8bit
      RTE_P_HvMgmt_DCDCWrkModActSts_Enum: nonqueued-sender-com-spec=data-element=tec_HvMgmt_DCDCWrkModActSts_Enum, provided-interface=IF_HvMgmt_DCDCWrkModActSts_Enum
      RTE_P_HvMgmt_DCFCDTC_8bit: nonqueued-sender-com-spec=data-element=tec_HvMgmt_DCFCDTC_8bit, provided-interface=IF_HvMgmt_DCFCDTC_8bit
      RTE_P_HvMgmt_DCFCReqSts_Flg: nonqueued-sender-com-spec=data-element=tec_HvMgmt_DCFCReqSts_Flg, provided-interface=IF_HvMgmt_DCFCReqSts_Flg
      RTE_P_HvMgmt_DCFCWrkModActSts_Enum: nonqueued-sender-com-spec=data-element=tec_HvMgmt_DCFCWrkModActSts_Enum, provided-interface=IF_HvMgmt_DCFCWrkModActSts_Enum
      RTE_P_HvMgmt_MCUDTC_8bit: nonqueued-sender-com-spec=data-element=tec_HvMgmt_MCUDTC_8bit, provided-interface=IF_HvMgmt_MCUDTC_8bit
      RTE_P_HvMgmt_MCUReqSts_Enum: nonqueued-sender-com-spec=data-element=tec_HvMgmt_MCUReqSts_Enum, provided-interface=IF_HvMgmt_MCUReqSts_Enum
      RTE_P_HvMgmt_MCUWrkModActSts_Enum: nonqueued-sender-com-spec=data-element=tec_HvMgmt_MCUWrkModActSts_Enum, provided-interface=IF_HvMgmt_MCUWrkModActSts_Enum
      RTE_P_HvMgmt_ReqDCDCMod_Enum: nonqueued-sender-com-spec=data-element=tec_HvMgmt_ReqDCDCMod_Enum, provided-interface=IF_HvMgmt_ReqDCDCMod_Enum
      RTE_P_HvMgmt_ReqModBMS_Flg: nonqueued-sender-com-spec=data-element=tec_HvMgmt_ReqModBMS_Flg, provided-interface=IF_HvMgmt_ReqModBMS_Flg
      RTE_P_HvMgmt_ReqTCUMod_Enum: nonqueued-sender-com-spec=data-element=tec_HvMgmt_ReqTCUMod_Enum, provided-interface=IF_HvMgmt_ReqTCUMod_Enum
      RTE_P_HvMgmt_TCUDTC_8bit: nonqueued-sender-com-spec=data-element=tec_HvMgmt_TCUDTC_8bit, provided-interface=IF_HvMgmt_TCUDTC_8bit
      RTE_P_HvMgmt_TCUWrkModActSts_Enum: nonqueued-sender-com-spec=data-element=tec_HvMgmt_TCUWrkModActSts_Enum, provided-interface=IF_HvMgmt_TCUWrkModActSts_Enum
    33 x require port:
      RTE_R_ChrMgmt_ChrgSts_Enum: nonqueued-receiver-com-spec{data-element=tec_ChrMgmt_ChrgSts_Enum, filter=data-filter-type=ALWAYS}, required-interface=IF_ChrMgmt_ChrgSts_Enum
      RTE_R_ChrMgmt_NegRlyOpenReq_Flg: nonqueued-receiver-com-spec{data-element=tec_ChrMgmt_NegRlyOpenReq_Flg, filter=data-filter-type=ALWAYS}, required-interface=IF_ChrMgmt_NegRlyOpenReq_Flg
      RTE_R_ChrMgmt_PreheatPODDiReq_Flg: nonqueued-receiver-com-spec{data-element=tec_ChrMgmt_PreheatPODDiReq_Flg, filter=data-filter-type=ALWAYS}, required-interface=IF_ChrMgmt_PreheatPODDiReq_Flg
      RTE_R_ChrMgmt_ReqHvRdy_Flg: nonqueued-receiver-com-spec{data-element=tec_ChrMgmt_ReqHvRdy_Flg, filter=data-filter-type=ALWAYS}, required-interface=IF_ChrMgmt_ReqHvRdy_Flg
      RTE_R_ComM_ACUDrvSeatBltSts_Flg: nonqueued-receiver-com-spec{data-element=tec_ComM_ACUDrvSeatBltSts_Flg, filter=data-filter-type=ALWAYS}, required-interface=IF_ComM_ACUDrvSeatBltSts_Flg
      RTE_R_ComM_ACUDrvSeatBltStsVld_Flg: nonqueued-receiver-com-spec{data-element=tec_ComM_ACUDrvSeatBltStsVld_Flg, filter=data-filter-type=ALWAYS}, required-interface=IF_ComM_ACUDrvSeatBltStsVld_Flg
      RTE_R_ComM_BCMImmoSts_Enum: nonqueued-receiver-com-spec{data-element=tec_ComM_BCMImmoSts_Enum, filter=data-filter-type=ALWAYS}, required-interface=IF_ComM_BCMImmoSts_Enum
      RTE_R_ComM_BMSBattDispSOC_pct: nonqueued-receiver-com-spec{data-element=tec_ComM_BMSBattDispSOC_pct, filter=data-filter-type=ALWAYS}, required-interface=IF_ComM_BMSBattDispSOC_pct
      RTE_R_ComM_BMSBattLnkUDc_V: nonqueued-receiver-com-spec{data-element=tec_ComM_BMSBattLnkUDc_V, filter=data-filter-type=ALWAYS}, required-interface=IF_ComM_BMSBattLnkUDc_V
      RTE_R_ComM_BMSChrgSts_Enum: nonqueued-receiver-com-spec{data-element=tec_ComM_BMSChrgSts_Enum, filter=data-filter-type=ALWAYS}, required-interface=IF_ComM_BMSChrgSts_Enum
      RTE_R_ComM_BMSNegRlySts_Enum: nonqueued-receiver-com-spec{data-element=tec_ComM_BMSNegRlySts_Enum, filter=data-filter-type=ALWAYS}, required-interface=IF_ComM_BMSNegRlySts_Enum
      RTE_R_ComM_BMSPosRlySts_Enum: nonqueued-receiver-com-spec{data-element=tec_ComM_BMSPosRlySts_Enum, filter=data-filter-type=ALWAYS}, required-interface=IF_ComM_BMSPosRlySts_Enum
      RTE_R_ComM_BMSRTCReq_Flg: nonqueued-receiver-com-spec{data-element=tec_ComM_BMSRTCReq_Flg, filter=data-filter-type=ALWAYS}, required-interface=IF_ComM_BMSRTCReq_Flg
      RTE_R_ComM_BMSWrkMod_Enum: nonqueued-receiver-com-spec{data-element=tec_ComM_BMSWrkMod_Enum, filter=data-filter-type=ALWAYS}, required-interface=IF_ComM_BMSWrkMod_Enum
      RTE_R_ComM_DCDCActLvUDc_V: nonqueued-receiver-com-spec{data-element=tec_ComM_DCDCActLvUDc_V, filter=data-filter-type=ALWAYS}, required-interface=IF_ComM_DCDCActLvUDc_V
      RTE_R_ComM_DCDCHvInpUDc_V: nonqueued-receiver-com-spec{data-element=tec_ComM_DCDCHvInpUDc_V, filter=data-filter-type=ALWAYS}, required-interface=IF_ComM_DCDCHvInpUDc_V
      RTE_R_ComM_DCDCWrkMod_Enum: nonqueued-receiver-com-spec{data-element=tec_ComM_DCDCWrkMod_Enum, filter=data-filter-type=ALWAYS}, required-interface=IF_ComM_DCDCWrkMod_Enum
      RTE_R_ComM_DCMFLDoorSts_Flg: nonqueued-receiver-com-spec{data-element=tec_ComM_DCMFLDoorSts_Flg, filter=data-filter-type=ALWAYS}, required-interface=IF_ComM_DCMFLDoorSts_Flg
      RTE_R_ComM_MCUUDc_V: nonqueued-receiver-com-spec{data-element=tec_ComM_MCUUDc_V, filter=data-filter-type=ALWAYS}, required-interface=IF_ComM_MCUUDc_V
      RTE_R_ComM_MCUWrkMod_Enum: nonqueued-receiver-com-spec{data-element=tec_ComM_MCUWrkMod_Enum, filter=data-filter-type=ALWAYS}, required-interface=IF_ComM_MCUWrkMod_Enum
      RTE_R_ComM_MotActTq_Nm: nonqueued-receiver-com-spec{data-element=tec_ComM_MotActTq_Nm, filter=data-filter-type=ALWAYS}, required-interface=IF_ComM_MotActTq_Nm
      RTE_R_ComM_PEPSPwrMod_Enum: nonqueued-receiver-com-spec{data-element=tec_ComM_PEPSPwrMod_Enum, filter=data-filter-type=ALWAYS}, required-interface=IF_ComM_PEPSPwrMod_Enum
      RTE_R_ComM_PODDcNegRlySts_Enum: nonqueued-receiver-com-spec{data-element=tec_ComM_PODDcNegRlySts_Enum, filter=data-filter-type=ALWAYS}, required-interface=IF_ComM_PODDcNegRlySts_Enum
      RTE_R_ComM_PODDcPosRlySts_Enum: nonqueued-receiver-com-spec{data-element=tec_ComM_PODDcPosRlySts_Enum, filter=data-filter-type=ALWAYS}, required-interface=IF_ComM_PODDcPosRlySts_Enum
      RTE_R_ComM_SGWRemHvCtrlReq_Enum: nonqueued-receiver-com-spec{data-element=tec_ComM_SGWRemHvCtrlReq_Enum, filter=data-filter-type=ALWAYS}, required-interface=IF_ComM_SGWRemHvCtrlReq_Enum
      RTE_R_ComM_SGWSysRdyReq_Flg: nonqueued-receiver-com-spec{data-element=tec_ComM_SGWSysRdyReq_Flg, filter=data-filter-type=ALWAYS}, required-interface=IF_ComM_SGWSysRdyReq_Flg
      RTE_R_DCChrg_DCFCClsReq_Flg: nonqueued-receiver-com-spec{data-element=tec_DCChrg_DCFCClsReq_Flg, filter=data-filter-type=ALWAYS}, required-interface=IF_DCChrg_DCFCClsReq_Flg
      RTE_R_ErrMgmt_HvCtrl_8bit: nonqueued-receiver-com-spec{data-element=tec_ErrMgmt_HvCtrl_8bit, filter=data-filter-type=ALWAYS}, required-interface=IF_ErrMgmt_HvCtrl_8bit
      RTE_R_GearMgmt_ActGear_Enum: nonqueued-receiver-com-spec{data-element=tec_GearMgmt_ActGear_Enum, filter=data-filter-type=ALWAYS}, required-interface=IF_GearMgmt_ActGear_Enum
      RTE_R_LvMgmt_IBSBattReChrgReq_Flg: nonqueued-receiver-com-spec{data-element=tec_LvMgmt_IBSBattReChrgReq_Flg, filter=data-filter-type=ALWAYS}, required-interface=IF_LvMgmt_IBSBattReChrgReq_Flg
      RTE_R_ModMgmt_HvSts_Enum: nonqueued-receiver-com-spec{data-element=tec_ModMgmt_HvSts_Enum, filter=data-filter-type=ALWAYS}, required-interface=IF_ModMgmt_HvSts_Enum
      RTE_R_VehMot_VehSpd_kph: nonqueued-receiver-com-spec{data-element=tec_VehMot_VehSpd_kph, filter=data-filter-type=ALWAYS}, required-interface=IF_VehMot_VehSpd_kph
      RTE_R_VehMot_VehSpdVld_Flg: nonqueued-receiver-com-spec{data-element=tec_VehMot_VehSpdVld_Flg, filter=data-filter-type=ALWAYS}, required-interface=IF_VehMot_VehSpdVld_Flg
    5 x component:
      CtAp_BMSMgmt: type=CtAp_BMSMgmt
      CtAp_DCDCMgmt: type=CtAp_DCDCMgmt
      CtAp_DCFCMgmt: type=CtAp_DCFCMgmt
      CtAp_MCUMgmt: type=CtAp_MCUMgmt
      CtAp_TCUMgmt: type=CtAp_TCUMgmt
    connect CtAp_BMSMgmt.RTE_P_HvMgmt_BMSNormHvDwnReq_Flg -> CtAp_DCDCMgmt.RTE_R_HvMgmt_BMSNormHvDwnReq_Flg
    connect CtAp_BMSMgmt.RTE_P_HvMgmt_BMSWrkModActSts_Enum -> CtAp_MCUMgmt.RTE_R_HvMgmt_BMSWrkModActSts_Enum
    connect CtAp_BMSMgmt.RTE_P_HvMgmt_BMSNormHvDwnReq_Flg -> CtAp_TCUMgmt.RTE_R_HvMgmt_BMSNormHvDwnReq_Flg
    connect CtAp_DCDCMgmt.RTE_P_HvMgmt_DCDCWrkModActSts_Enum -> CtAp_TCUMgmt.RTE_R_HvMgmt_DCDCWrkModActSts_Enum
    connect CtAp_TCUMgmt.RTE_P_HvMgmt_TCUWrkModActSts_Enum -> CtAp_BMSMgmt.RTE_R_HvMgmt_TCUWrkModActSts_Enum
    delegate CtAp_BMSMgmt.RTE_P_HvMgmt_BMSDTC_8bit <-> outer port CtAp_HvMgmt/RTE_P_HvMgmt_BMSDTC_8bit
    delegate CtAp_BMSMgmt.RTE_P_HvMgmt_BMSNegRlyActSts_Enum <-> outer port CtAp_HvMgmt/RTE_P_HvMgmt_BMSNegRlyActSts_Enum
    delegate CtAp_BMSMgmt.RTE_P_HvMgmt_BMSNegRlyCtrlReq_Flg <-> outer port CtAp_HvMgmt/RTE_P_HvMgmt_BMSNegRlyCtrlReq_Flg
    delegate CtAp_BMSMgmt.RTE_P_HvMgmt_BMSPosRlyActSts_Enum <-> outer port CtAp_HvMgmt/RTE_P_HvMgmt_BMSPosRlyActSts_Enum
    delegate CtAp_BMSMgmt.RTE_P_HvMgmt_BMSWrkModActSts_Enum <-> outer port CtAp_HvMgmt/RTE_P_HvMgmt_BMSWrkModActSts_Enum
    delegate CtAp_DCDCMgmt.RTE_P_HvMgmt_DCDCDmdLvUDc_V <-> outer port CtAp_HvMgmt/RTE_P_HvMgmt_DCDCDmdLvUDc_V
    delegate CtAp_DCDCMgmt.RTE_P_HvMgmt_DCDCDTC_8bit <-> outer port CtAp_HvMgmt/RTE_P_HvMgmt_DCDCDTC_8bit
    delegate CtAp_DCDCMgmt.RTE_P_HvMgmt_DCDCWrkModActSts_Enum <-> outer port CtAp_HvMgmt/RTE_P_HvMgmt_DCDCWrkModActSts_Enum
    delegate CtAp_DCFCMgmt.RTE_P_HvMgmt_DCFCDTC_8bit <-> outer port CtAp_HvMgmt/RTE_P_HvMgmt_DCFCDTC_8bit
    delegate CtAp_DCFCMgmt.RTE_P_HvMgmt_DCFCReqSts_Flg <-> outer port CtAp_HvMgmt/RTE_P_HvMgmt_DCFCReqSts_Flg
    delegate CtAp_DCFCMgmt.RTE_P_HvMgmt_DCFCWrkModActSts_Enum <-> outer port CtAp_HvMgmt/RTE_P_HvMgmt_DCFCWrkModActSts_Enum
    delegate CtAp_MCUMgmt.RTE_P_HvMgmt_MCUDTC_8bit <-> outer port CtAp_HvMgmt/RTE_P_HvMgmt_MCUDTC_8bit
    delegate CtAp_MCUMgmt.RTE_P_HvMgmt_MCUReqSts_Enum <-> outer port CtAp_HvMgmt/RTE_P_HvMgmt_MCUReqSts_Enum
    delegate CtAp_MCUMgmt.RTE_P_HvMgmt_MCUWrkModActSts_Enum <-> outer port CtAp_HvMgmt/RTE_P_HvMgmt_MCUWrkModActSts_Enum
    delegate CtAp_DCDCMgmt.RTE_P_HvMgmt_ReqDCDCMod_Enum <-> outer port CtAp_HvMgmt/RTE_P_HvMgmt_ReqDCDCMod_Enum
    delegate CtAp_BMSMgmt.RTE_P_HvMgmt_ReqModBMS_Flg <-> outer port CtAp_HvMgmt/RTE_P_HvMgmt_ReqModBMS_Flg
    delegate CtAp_TCUMgmt.RTE_P_HvMgmt_ReqTCUMod_Enum <-> outer port CtAp_HvMgmt/RTE_P_HvMgmt_ReqTCUMod_Enum
    delegate CtAp_TCUMgmt.RTE_P_HvMgmt_TCUDTC_8bit <-> outer port CtAp_HvMgmt/RTE_P_HvMgmt_TCUDTC_8bit
    delegate CtAp_TCUMgmt.RTE_P_HvMgmt_TCUWrkModActSts_Enum <-> outer port CtAp_HvMgmt/RTE_P_HvMgmt_TCUWrkModActSts_Enum
    delegate CtAp_BMSMgmt.RTE_R_ChrMgmt_ChrgSts_Enum <-> outer port CtAp_HvMgmt/RTE_R_ChrMgmt_ChrgSts_Enum
    delegate CtAp_DCDCMgmt.RTE_R_ChrMgmt_ChrgSts_Enum <-> outer port CtAp_HvMgmt/RTE_R_ChrMgmt_ChrgSts_Enum
    delegate CtAp_MCUMgmt.RTE_R_ChrMgmt_ChrgSts_Enum <-> outer port CtAp_HvMgmt/RTE_R_ChrMgmt_ChrgSts_Enum
    delegate CtAp_BMSMgmt.RTE_R_ChrMgmt_NegRlyOpenReq_Flg <-> outer port CtAp_HvMgmt/RTE_R_ChrMgmt_NegRlyOpenReq_Flg
    delegate CtAp_DCDCMgmt.RTE_R_ChrMgmt_PreheatPODDiReq_Flg <-> outer port CtAp_HvMgmt/RTE_R_ChrMgmt_PreheatPODDiReq_Flg
    delegate CtAp_BMSMgmt.RTE_R_ChrMgmt_ReqHvRdy_Flg <-> outer port CtAp_HvMgmt/RTE_R_ChrMgmt_ReqHvRdy_Flg
    delegate CtAp_MCUMgmt.RTE_R_ComM_ACUDrvSeatBltSts_Flg <-> outer port CtAp_HvMgmt/RTE_R_ComM_ACUDrvSeatBltSts_Flg
    delegate CtAp_MCUMgmt.RTE_R_ComM_ACUDrvSeatBltStsVld_Flg <-> outer port CtAp_HvMgmt/RTE_R_ComM_ACUDrvSeatBltStsVld_Flg
    delegate CtAp_MCUMgmt.RTE_R_ComM_BCMImmoSts_Enum <-> outer port CtAp_HvMgmt/RTE_R_ComM_BCMImmoSts_Enum
    delegate CtAp_BMSMgmt.RTE_R_ComM_BMSBattDispSOC_pct <-> outer port CtAp_HvMgmt/RTE_R_ComM_BMSBattDispSOC_pct
    delegate CtAp_BMSMgmt.RTE_R_ComM_BMSBattLnkUDc_V <-> outer port CtAp_HvMgmt/RTE_R_ComM_BMSBattLnkUDc_V
    delegate CtAp_DCDCMgmt.RTE_R_ComM_BMSBattLnkUDc_V <-> outer port CtAp_HvMgmt/RTE_R_ComM_BMSBattLnkUDc_V
    delegate CtAp_DCDCMgmt.RTE_R_ComM_BMSChrgSts_Enum <-> outer port CtAp_HvMgmt/RTE_R_ComM_BMSChrgSts_Enum
    delegate CtAp_BMSMgmt.RTE_R_ComM_BMSNegRlySts_Enum <-> outer port CtAp_HvMgmt/RTE_R_ComM_BMSNegRlySts_Enum
    delegate CtAp_BMSMgmt.RTE_R_ComM_BMSPosRlySts_Enum <-> outer port CtAp_HvMgmt/RTE_R_ComM_BMSPosRlySts_Enum
    delegate CtAp_BMSMgmt.RTE_R_ComM_BMSRTCReq_Flg <-> outer port CtAp_HvMgmt/RTE_R_ComM_BMSRTCReq_Flg
    delegate CtAp_BMSMgmt.RTE_R_ComM_BMSWrkMod_Enum <-> outer port CtAp_HvMgmt/RTE_R_ComM_BMSWrkMod_Enum
    delegate CtAp_DCDCMgmt.RTE_R_ComM_DCDCActLvUDc_V <-> outer port CtAp_HvMgmt/RTE_R_ComM_DCDCActLvUDc_V
    delegate CtAp_BMSMgmt.RTE_R_ComM_DCDCHvInpUDc_V <-> outer port CtAp_HvMgmt/RTE_R_ComM_DCDCHvInpUDc_V
    delegate CtAp_DCDCMgmt.RTE_R_ComM_DCDCHvInpUDc_V <-> outer port CtAp_HvMgmt/RTE_R_ComM_DCDCHvInpUDc_V
    delegate CtAp_DCDCMgmt.RTE_R_ComM_DCDCWrkMod_Enum <-> outer port CtAp_HvMgmt/RTE_R_ComM_DCDCWrkMod_Enum
    delegate CtAp_MCUMgmt.RTE_R_ComM_DCMFLDoorSts_Flg <-> outer port CtAp_HvMgmt/RTE_R_ComM_DCMFLDoorSts_Flg
    delegate CtAp_BMSMgmt.RTE_R_ComM_MCUUDc_V <-> outer port CtAp_HvMgmt/RTE_R_ComM_MCUUDc_V
    delegate CtAp_MCUMgmt.RTE_R_ComM_MCUWrkMod_Enum <-> outer port CtAp_HvMgmt/RTE_R_ComM_MCUWrkMod_Enum
    delegate CtAp_TCUMgmt.RTE_R_ComM_MotActTq_Nm <-> outer port CtAp_HvMgmt/RTE_R_ComM_MotActTq_Nm
    delegate CtAp_BMSMgmt.RTE_R_ComM_PEPSPwrMod_Enum <-> outer port CtAp_HvMgmt/RTE_R_ComM_PEPSPwrMod_Enum
    delegate CtAp_MCUMgmt.RTE_R_ComM_PEPSPwrMod_Enum <-> outer port CtAp_HvMgmt/RTE_R_ComM_PEPSPwrMod_Enum
    delegate CtAp_DCFCMgmt.RTE_R_ComM_PODDcNegRlySts_Enum <-> outer port CtAp_HvMgmt/RTE_R_ComM_PODDcNegRlySts_Enum
    delegate CtAp_DCFCMgmt.RTE_R_ComM_PODDcPosRlySts_Enum <-> outer port CtAp_HvMgmt/RTE_R_ComM_PODDcPosRlySts_Enum
    delegate CtAp_BMSMgmt.RTE_R_ComM_SGWRemHvCtrlReq_Enum <-> outer port CtAp_HvMgmt/RTE_R_ComM_SGWRemHvCtrlReq_Enum
    delegate CtAp_MCUMgmt.RTE_R_ComM_SGWSysRdyReq_Flg <-> outer port CtAp_HvMgmt/RTE_R_ComM_SGWSysRdyReq_Flg
    delegate CtAp_DCFCMgmt.RTE_R_DCChrg_DCFCClsReq_Flg <-> outer port CtAp_HvMgmt/RTE_R_DCChrg_DCFCClsReq_Flg
    delegate CtAp_BMSMgmt.RTE_R_ErrMgmt_HvCtrl_8bit <-> outer port CtAp_HvMgmt/RTE_R_ErrMgmt_HvCtrl_8bit
    delegate CtAp_DCDCMgmt.RTE_R_ErrMgmt_HvCtrl_8bit <-> outer port CtAp_HvMgmt/RTE_R_ErrMgmt_HvCtrl_8bit
    delegate CtAp_MCUMgmt.RTE_R_ErrMgmt_HvCtrl_8bit <-> outer port CtAp_HvMgmt/RTE_R_ErrMgmt_HvCtrl_8bit
    delegate CtAp_TCUMgmt.RTE_R_ErrMgmt_HvCtrl_8bit <-> outer port CtAp_HvMgmt/RTE_R_ErrMgmt_HvCtrl_8bit
    delegate CtAp_BMSMgmt.RTE_R_GearMgmt_ActGear_Enum <-> outer port CtAp_HvMgmt/RTE_R_GearMgmt_ActGear_Enum
    delegate CtAp_MCUMgmt.RTE_R_GearMgmt_ActGear_Enum <-> outer port CtAp_HvMgmt/RTE_R_GearMgmt_ActGear_Enum
    delegate CtAp_BMSMgmt.RTE_R_LvMgmt_IBSBattReChrgReq_Flg <-> outer port CtAp_HvMgmt/RTE_R_LvMgmt_IBSBattReChrgReq_Flg
    delegate CtAp_BMSMgmt.RTE_R_ModMgmt_HvSts_Enum <-> outer port CtAp_HvMgmt/RTE_R_ModMgmt_HvSts_Enum
    delegate CtAp_DCDCMgmt.RTE_R_ModMgmt_HvSts_Enum <-> outer port CtAp_HvMgmt/RTE_R_ModMgmt_HvSts_Enum
    delegate CtAp_MCUMgmt.RTE_R_ModMgmt_HvSts_Enum <-> outer port CtAp_HvMgmt/RTE_R_ModMgmt_HvSts_Enum
    delegate CtAp_TCUMgmt.RTE_R_ModMgmt_HvSts_Enum <-> outer port CtAp_HvMgmt/RTE_R_ModMgmt_HvSts_Enum
    delegate CtAp_BMSMgmt.RTE_R_VehMot_VehSpd_kph <-> outer port CtAp_HvMgmt/RTE_R_VehMot_VehSpd_kph
    delegate CtAp_BMSMgmt.RTE_R_VehMot_VehSpdVld_Flg <-> outer port CtAp_HvMgmt/RTE_R_VehMot_VehSpdVld_Flg
  5 x swc implementation:
    CtAp_BMSMgmt_Implementation: behavior=CtAp_BMSMgmt_InternalBehavior
      code-descriptors:
        code Default: artifact-descriptors=autosar-engineering-object={short-label=Default, category=SWOBJ}
    CtAp_DCDCMgmt_Implementation: behavior=CtAp_DCDCMgmt_InternalBehavior
      code-descriptors:
        code Default: artifact-descriptors=autosar-engineering-object={short-label=Default, category=SWOBJ}
    CtAp_DCFCMgmt_Implementation: behavior=CtAp_DCFCMgmt_InternalBehavior
      code-descriptors:
        code Default: artifact-descriptors=autosar-engineering-object={short-label=Default, category=SWOBJ}
    CtAp_MCUMgmt_Implementation: behavior=CtAp_MCUMgmt_InternalBehavior
      code-descriptors:
        code Default: artifact-descriptors=autosar-engineering-object={short-label=Default, category=SWOBJ}
    CtAp_TCUMgmt_Implementation: behavior=CtAp_TCUMgmt_InternalBehavior
      code-descriptors:
        code Default: artifact-descriptors=autosar-engineering-object={short-label=Default, category=SWOBJ}
package /PortInterfaces
  53 x sender receiver interface:
    IF_ChrMgmt_ChrgSts_Enum: invalidation-policy{data-element=tec_ChrMgmt_ChrgSts_Enum, handle-invalid=DONT-INVALIDATE}
      data tec_ChrMgmt_ChrgSts_Enum: type=uint8
    IF_ChrMgmt_NegRlyOpenReq_Flg: invalidation-policy{data-element=tec_ChrMgmt_NegRlyOpenReq_Flg, handle-invalid=DONT-INVALIDATE}
      data tec_ChrMgmt_NegRlyOpenReq_Flg: type=boolean
    IF_ChrMgmt_PreheatPODDiReq_Flg: invalidation-policy{data-element=tec_ChrMgmt_PreheatPODDiReq_Flg, handle-invalid=DONT-INVALIDATE}
      data tec_ChrMgmt_PreheatPODDiReq_Flg: type=boolean
    IF_ChrMgmt_ReqHvRdy_Flg: invalidation-policy{data-element=tec_ChrMgmt_ReqHvRdy_Flg, handle-invalid=DONT-INVALIDATE}
      data tec_ChrMgmt_ReqHvRdy_Flg: type=boolean
    IF_ComM_ACUDrvSeatBltSts_Flg: invalidation-policy{data-element=tec_ComM_ACUDrvSeatBltSts_Flg, handle-invalid=DONT-INVALIDATE}
      data tec_ComM_ACUDrvSeatBltSts_Flg: type=boolean
    IF_ComM_ACUDrvSeatBltStsVld_Flg: invalidation-policy{data-element=tec_ComM_ACUDrvSeatBltStsVld_Flg, handle-invalid=DONT-INVALIDATE}
      data tec_ComM_ACUDrvSeatBltStsVld_Flg: type=boolean
    IF_ComM_BCMImmoSts_Enum: invalidation-policy{data-element=tec_ComM_BCMImmoSts_Enum, handle-invalid=DONT-INVALIDATE}
      data tec_ComM_BCMImmoSts_Enum: type=uint8
    IF_ComM_BMSBattDispSOC_pct: invalidation-policy{data-element=tec_ComM_BMSBattDispSOC_pct, handle-invalid=DONT-INVALIDATE}
      data tec_ComM_BMSBattDispSOC_pct: type=float32
    IF_ComM_BMSBattLnkUDc_V: invalidation-policy{data-element=tec_ComM_BMSBattLnkUDc_V, handle-invalid=DONT-INVALIDATE}
      data tec_ComM_BMSBattLnkUDc_V: type=float32
    IF_ComM_BMSChrgSts_Enum: invalidation-policy{data-element=tec_ComM_BMSChrgSts_Enum, handle-invalid=DONT-INVALIDATE}
      data tec_ComM_BMSChrgSts_Enum: type=uint8
    IF_ComM_BMSNegRlySts_Enum: invalidation-policy{data-element=tec_ComM_BMSNegRlySts_Enum, handle-invalid=DONT-INVALIDATE}
      data tec_ComM_BMSNegRlySts_Enum: type=uint8
    IF_ComM_BMSPosRlySts_Enum: invalidation-policy{data-element=tec_ComM_BMSPosRlySts_Enum, handle-invalid=DONT-INVALIDATE}
      data tec_ComM_BMSPosRlySts_Enum: type=uint8
    IF_ComM_BMSRTCReq_Flg: invalidation-policy{data-element=tec_ComM_BMSRTCReq_Flg, handle-invalid=DONT-INVALIDATE}
      data tec_ComM_BMSRTCReq_Flg: type=boolean
    IF_ComM_BMSWrkMod_Enum: invalidation-policy{data-element=tec_ComM_BMSWrkMod_Enum, handle-invalid=DONT-INVALIDATE}
      data tec_ComM_BMSWrkMod_Enum: type=uint8
    IF_ComM_DCDCActLvUDc_V: invalidation-policy{data-element=tec_ComM_DCDCActLvUDc_V, handle-invalid=DONT-INVALIDATE}
      data tec_ComM_DCDCActLvUDc_V: type=float32
    IF_ComM_DCDCHvInpUDc_V: invalidation-policy{data-element=tec_ComM_DCDCHvInpUDc_V, handle-invalid=DONT-INVALIDATE}
      data tec_ComM_DCDCHvInpUDc_V: type=float32
    IF_ComM_DCDCWrkMod_Enum: invalidation-policy{data-element=tec_ComM_DCDCWrkMod_Enum, handle-invalid=DONT-INVALIDATE}
      data tec_ComM_DCDCWrkMod_Enum: type=uint8
    IF_ComM_DCMFLDoorSts_Flg: invalidation-policy{data-element=tec_ComM_DCMFLDoorSts_Flg, handle-invalid=DONT-INVALIDATE}
      data tec_ComM_DCMFLDoorSts_Flg: type=boolean
    IF_ComM_MCUUDc_V: invalidation-policy{data-element=tec_ComM_MCUUDc_V, handle-invalid=DONT-INVALIDATE}
      data tec_ComM_MCUUDc_V: type=float32
    IF_ComM_MCUWrkMod_Enum: invalidation-policy{data-element=tec_ComM_MCUWrkMod_Enum, handle-invalid=DONT-INVALIDATE}
      data tec_ComM_MCUWrkMod_Enum: type=uint8
    IF_ComM_MotActTq_Nm: invalidation-policy{data-element=tec_ComM_MotActTq_Nm, handle-invalid=DONT-INVALIDATE}
      data tec_ComM_MotActTq_Nm: type=float32
    IF_ComM_PEPSPwrMod_Enum: invalidation-policy{data-element=tec_ComM_PEPSPwrMod_Enum, handle-invalid=DONT-INVALIDATE}
      data tec_ComM_PEPSPwrMod_Enum: type=uint8
    IF_ComM_PODDcNegRlySts_Enum: invalidation-policy{data-element=tec_ComM_PODDcNegRlySts_Enum, handle-invalid=DONT-INVALIDATE}
      data tec_ComM_PODDcNegRlySts_Enum: type=uint8
    IF_ComM_PODDcPosRlySts_Enum: invalidation-policy{data-element=tec_ComM_PODDcPosRlySts_Enum, handle-invalid=DONT-INVALIDATE}
      data tec_ComM_PODDcPosRlySts_Enum: type=uint8
    IF_ComM_SGWRemHvCtrlReq_Enum: invalidation-policy{data-element=tec_ComM_SGWRemHvCtrlReq_Enum, handle-invalid=DONT-INVALIDATE}
      data tec_ComM_SGWRemHvCtrlReq_Enum: type=uint8
    IF_ComM_SGWSysRdyReq_Flg: invalidation-policy{data-element=tec_ComM_SGWSysRdyReq_Flg, handle-invalid=DONT-INVALIDATE}
      data tec_ComM_SGWSysRdyReq_Flg: type=boolean
    IF_DCChrg_DCFCClsReq_Flg: invalidation-policy{data-element=tec_DCChrg_DCFCClsReq_Flg, handle-invalid=DONT-INVALIDATE}
      data tec_DCChrg_DCFCClsReq_Flg: type=boolean
    IF_ErrMgmt_HvCtrl_8bit: invalidation-policy{data-element=tec_ErrMgmt_HvCtrl_8bit, handle-invalid=DONT-INVALIDATE}
      data tec_ErrMgmt_HvCtrl_8bit: type=uint8
    IF_GearMgmt_ActGear_Enum: invalidation-policy{data-element=tec_GearMgmt_ActGear_Enum, handle-invalid=DONT-INVALIDATE}
      data tec_GearMgmt_ActGear_Enum: type=uint8
    IF_HvMgmt_BMSDTC_8bit: invalidation-policy{data-element=tec_HvMgmt_BMSDTC_8bit, handle-invalid=DONT-INVALIDATE}
      data tec_HvMgmt_BMSDTC_8bit: type=uint8
    IF_HvMgmt_BMSNegRlyActSts_Enum: invalidation-policy{data-element=tec_HvMgmt_BMSNegRlyActSts_Enum, handle-invalid=DONT-INVALIDATE}
      data tec_HvMgmt_BMSNegRlyActSts_Enum: type=uint8
    IF_HvMgmt_BMSNegRlyCtrlReq_Flg: invalidation-policy{data-element=tec_HvMgmt_BMSNegRlyCtrlReq_Flg, handle-invalid=DONT-INVALIDATE}
      data tec_HvMgmt_BMSNegRlyCtrlReq_Flg: type=boolean
    IF_HvMgmt_BMSNormHvDwnReq_Flg: invalidation-policy{data-element=tec_HvMgmt_BMSNormHvDwnReq_Flg, handle-invalid=DONT-INVALIDATE}
      data tec_HvMgmt_BMSNormHvDwnReq_Flg: type=boolean
    IF_HvMgmt_BMSPosRlyActSts_Enum: invalidation-policy{data-element=tec_HvMgmt_BMSPosRlyActSts_Enum, handle-invalid=DONT-INVALIDATE}
      data tec_HvMgmt_BMSPosRlyActSts_Enum: type=uint8
    IF_HvMgmt_BMSWrkModActSts_Enum: invalidation-policy{data-element=tec_HvMgmt_BMSWrkModActSts_Enum, handle-invalid=DONT-INVALIDATE}
      data tec_HvMgmt_BMSWrkModActSts_Enum: type=uint8
    IF_HvMgmt_DCDCDmdLvUDc_V: invalidation-policy{data-element=tec_HvMgmt_DCDCDmdLvUDc_V, handle-invalid=DONT-INVALIDATE}
      data tec_HvMgmt_DCDCDmdLvUDc_V: type=float32
    IF_HvMgmt_DCDCDTC_8bit: invalidation-policy{data-element=tec_HvMgmt_DCDCDTC_8bit, handle-invalid=DONT-INVALIDATE}
      data tec_HvMgmt_DCDCDTC_8bit: type=uint8
    IF_HvMgmt_DCDCWrkModActSts_Enum: invalidation-policy{data-element=tec_HvMgmt_DCDCWrkModActSts_Enum, handle-invalid=DONT-INVALIDATE}
      data tec_HvMgmt_DCDCWrkModActSts_Enum: type=uint8
    IF_HvMgmt_DCFCDTC_8bit: invalidation-policy{data-element=tec_HvMgmt_DCFCDTC_8bit, handle-invalid=DONT-INVALIDATE}
      data tec_HvMgmt_DCFCDTC_8bit: type=uint8
    IF_HvMgmt_DCFCReqSts_Flg: invalidation-policy{data-element=tec_HvMgmt_DCFCReqSts_Flg, handle-invalid=DONT-INVALIDATE}
      data tec_HvMgmt_DCFCReqSts_Flg: type=boolean
    IF_HvMgmt_DCFCWrkModActSts_Enum: invalidation-policy{data-element=tec_HvMgmt_DCFCWrkModActSts_Enum, handle-invalid=DONT-INVALIDATE}
      data tec_HvMgmt_DCFCWrkModActSts_Enum: type=uint8
    IF_HvMgmt_MCUDTC_8bit: invalidation-policy{data-element=tec_HvMgmt_MCUDTC_8bit, handle-invalid=DONT-INVALIDATE}
      data tec_HvMgmt_MCUDTC_8bit: type=uint8
    IF_HvMgmt_MCUReqSts_Enum: invalidation-policy{data-element=tec_HvMgmt_MCUReqSts_Enum, handle-invalid=DONT-INVALIDATE}
      data tec_HvMgmt_MCUReqSts_Enum: type=uint8
    IF_HvMgmt_MCUWrkModActSts_Enum: invalidation-policy{data-element=tec_HvMgmt_MCUWrkModActSts_Enum, handle-invalid=DONT-INVALIDATE}
      data tec_HvMgmt_MCUWrkModActSts_Enum: type=uint8
    IF_HvMgmt_ReqDCDCMod_Enum: invalidation-policy{data-element=tec_HvMgmt_ReqDCDCMod_Enum, handle-invalid=DONT-INVALIDATE}
      data tec_HvMgmt_ReqDCDCMod_Enum: type=uint8
    IF_HvMgmt_ReqModBMS_Flg: invalidation-policy{data-element=tec_HvMgmt_ReqModBMS_Flg, handle-invalid=DONT-INVALIDATE}
      data tec_HvMgmt_ReqModBMS_Flg: type=boolean
    IF_HvMgmt_ReqTCUMod_Enum: invalidation-policy{data-element=tec_HvMgmt_ReqTCUMod_Enum, handle-invalid=DONT-INVALIDATE}
      data tec_HvMgmt_ReqTCUMod_Enum: type=uint8
    IF_HvMgmt_TCUDTC_8bit: invalidation-policy{data-element=tec_HvMgmt_TCUDTC_8bit, handle-invalid=DONT-INVALIDATE}
      data tec_HvMgmt_TCUDTC_8bit: type=uint8
    IF_HvMgmt_TCUWrkModActSts_Enum: invalidation-policy{data-element=tec_HvMgmt_TCUWrkModActSts_Enum, handle-invalid=DONT-INVALIDATE}
      data tec_HvMgmt_TCUWrkModActSts_Enum: type=uint8
    IF_LvMgmt_IBSBattReChrgReq_Flg: invalidation-policy{data-element=tec_LvMgmt_IBSBattReChrgReq_Flg, handle-invalid=DONT-INVALIDATE}
      data tec_LvMgmt_IBSBattReChrgReq_Flg: type=boolean
    IF_ModMgmt_HvSts_Enum: invalidation-policy{data-element=tec_ModMgmt_HvSts_Enum, handle-invalid=DONT-INVALIDATE}
      data tec_ModMgmt_HvSts_Enum: type=uint8
    IF_VehMot_VehSpd_kph: invalidation-policy{data-element=tec_VehMot_VehSpd_kph, handle-invalid=DONT-INVALIDATE}
      data tec_VehMot_VehSpd_kph: type=float32
    IF_VehMot_VehSpdVld_Flg: invalidation-policy{data-element=tec_VehMot_VehSpdVld_Flg, handle-invalid=DONT-INVALIDATE}
      data tec_VehMot_VehSpdVld_Flg: type=boolean
